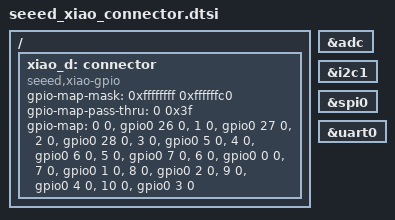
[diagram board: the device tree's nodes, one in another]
/*
 * SPDX-FileCopyrightText: Copyright (c) 2026 Navimatix GmbH
 * SPDX-FileCopyrightText: Copyright (c) 2026 TiaC Systems
 * SPDX-License-Identifier: Apache-2.0
 */

/ {
	xiao_d: connector {
		compatible = "seeed,xiao-gpio";
		#gpio-cells = <2>;
		gpio-map-mask = <0xffffffff 0xffffffc0>;
		gpio-map-pass-thru = <0 0x3f>;
		gpio-map = <0 0 &gpio0 26 0>,	/* D0 (ADC0) */
			   <1 0 &gpio0 27 0>,	/* D1 (ADC1) */
			   <2 0 &gpio0 28 0>,	/* D2 (ADC2) */
			   <3 0 &gpio0 5 0>,	/* D3 (SPI0-CS) */
			   <4 0 &gpio0 6 0>,	/* D4 (I2C1-SDA) */
			   <5 0 &gpio0 7 0>,	/* D5 (I2C1-SCL) */
			   <6 0 &gpio0 0 0>,	/* D6 (UART0-TX) */
			   <7 0 &gpio0 1 0>,	/* D7 (UART0-RX) */
			   <8 0 &gpio0 2 0>,	/* D8 (SPI0-SCK) */
			   <9 0 &gpio0 4 0>,	/* D9 (SPI0-MISO) */
			   <10 0 &gpio0 3 0>;	/* D10 (SPI0-MOSI) */
	};
};

xiao_adc: &adc {};

xiao_i2c: &i2c1 {};

xiao_spi: &spi0 {};

xiao_serial: &uart0 {};
